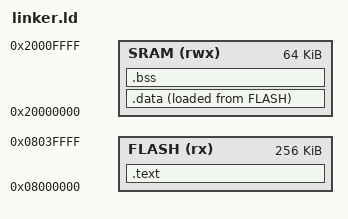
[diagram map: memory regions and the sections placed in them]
ENTRY(main)

MEMORY
{
    FLASH (rx) : ORIGIN = 0x08000000, LENGTH = 256K
    SRAM (rwx) : ORIGIN = 0x20000000, LENGTH = 64K
}

SECTIONS
{
    .text : {
        *(.text*)
    } > FLASH

    .data : {
        *(.data*)
    } > SRAM AT > FLASH

    .bss : {
        *(.bss*)
    } > SRAM
}
